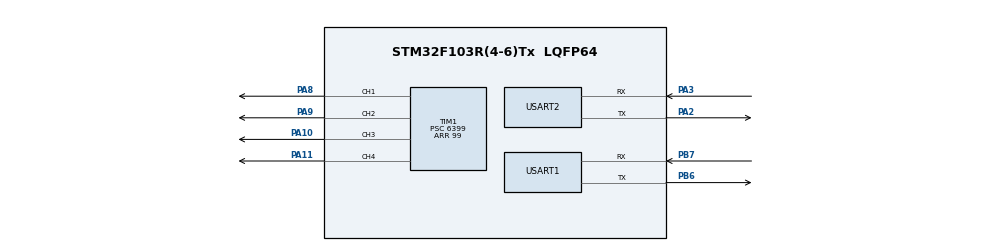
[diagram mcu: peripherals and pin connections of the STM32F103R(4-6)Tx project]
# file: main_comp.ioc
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Dma.Request0=USART1_RX
Dma.Request1=USART1_TX
Dma.USART1_RX.0.Direction=DMA_PERIPH_TO_MEMORY
Dma.USART1_RX.0.Instance=DMA1_Channel5
Dma.USART1_RX.0.MemDataAlignment=DMA_MDATAALIGN_BYTE
Dma.USART1_RX.0.MemInc=DMA_MINC_ENABLE
Dma.USART1_RX.0.Mode=DMA_NORMAL
Dma.USART1_RX.0.PeriphDataAlignment=DMA_PDATAALIGN_BYTE
Dma.USART1_RX.0.PeriphInc=DMA_PINC_DISABLE
Dma.USART1_RX.0.Priority=DMA_PRIORITY_LOW
Dma.USART1_TX.1.Direction=DMA_MEMORY_TO_PERIPH
Dma.USART1_TX.1.Instance=DMA1_Channel4
Dma.USART1_TX.1.MemDataAlignment=DMA_MDATAALIGN_BYTE
Dma.USART1_TX.1.MemInc=DMA_MINC_ENABLE
Dma.USART1_TX.1.Mode=DMA_NORMAL
Dma.USART1_TX.1.PeriphDataAlignment=DMA_PDATAALIGN_BYTE
Dma.USART1_TX.1.PeriphInc=DMA_PINC_DISABLE
Dma.USART1_TX.1.Priority=DMA_PRIORITY_LOW
Mcu.Family=STM32F1
Mcu.Name=STM32F103R(4-6)Tx
Mcu.Package=LQFP64
NVIC.DMA1_Channel4_IRQn=true\:0\:0\:false\:false\:true\:false\:true
NVIC.DMA1_Channel5_IRQn=true\:0\:0\:false\:false\:true\:false\:true
NVIC.PriorityGroup=NVIC_PRIORITYGROUP_4
NVIC.USART2_IRQn=true\:0\:0\:false\:false\:true\:true\:true
PA10.Signal=S_TIM1_CH3
PA11.Signal=S_TIM1_CH4
PA2.Mode=Asynchronous
PA2.Signal=USART2_TX
PA3.Mode=Asynchronous
PA3.Signal=USART2_RX
PA8.Signal=S_TIM1_CH1
PA9.Signal=S_TIM1_CH2
PB6.Mode=Asynchronous
PB6.Signal=USART1_TX
PB7.Mode=Asynchronous
PB7.Signal=USART1_RX
ProjectManager.HeapSize=0x200
ProjectManager.StackSize=0x400
ProjectManager.TargetToolchain=MDK-ARM V5.27
RCC.APB1Freq_Value=8000000
RCC.APB2Freq_Value=8000000
SH.S_TIM1_CH1.0=TIM1_CH1,PWM Generation1 CH1
SH.S_TIM1_CH2.0=TIM1_CH2,PWM Generation2 CH2
SH.S_TIM1_CH3.0=TIM1_CH3,PWM Generation3 CH3
SH.S_TIM1_CH4.0=TIM1_CH4,PWM Generation4 CH4
TIM1.Channel-PWM\ Generation1\ CH1=TIM_CHANNEL_1
TIM1.Channel-PWM\ Generation2\ CH2=TIM_CHANNEL_2
TIM1.Channel-PWM\ Generation3\ CH3=TIM_CHANNEL_3
TIM1.Channel-PWM\ Generation4\ CH4=TIM_CHANNEL_4
TIM1.Period=99
TIM1.Prescaler=6399
USART1.VirtualMode=VM_ASYNC
USART2.VirtualMode=VM_ASYNC
VP_SYS_VS_ND.Mode=No_Debug
board=custom

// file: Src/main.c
/* USER CODE BEGIN Header */
/**
  ******************************************************************************
  * @file           : main.c
  * @brief          : Main program body
  ******************************************************************************
  * @attention
  *
  * <h2><center>&copy; Copyright (c) 2020 STMicroelectronics.
  * All rights reserved.</center></h2>
  *
  * This software component is licensed by ST under BSD 3-Clause license,
  * the "License"; You may not use this file except in compliance with the
  * License. You may obtain a copy of the License at:
  *                        opensource.org/licenses/BSD-3-Clause
  *
  ******************************************************************************
  */
/* USER CODE END Header */

#include "main.h"
#include "stdio.h"
#include "string.h"
#include "stdlib.h"

/* USER CODE BEGIN PM */
void run(uint32_t, uint32_t);
/* USER CODE END PM */

TIM_HandleTypeDef htim1;

UART_HandleTypeDef huart1;
UART_HandleTypeDef huart2;
DMA_HandleTypeDef hdma_usart1_rx;
DMA_HandleTypeDef hdma_usart1_tx;

void SystemClock_Config(void);
static void MX_GPIO_Init(void);
static void MX_DMA_Init(void);
static void MX_TIM1_Init(void);
static void MX_USART1_UART_Init(void);
static void MX_USART2_UART_Init(void);
void run_motor(int, int);

/* USER CODE BEGIN 0 */
char recieved_data[32];
int flag = 0;
/* USER CODE END 0 */

int main(void)
{
  /* USER CODE BEGIN 1 */
	uint16_t val=0;
  /* USER CODE END 1 */

  /* MCU Configuration--------------------------------------------------------*/

  /* Reset of all peripherals, Initializes the Flash interface and the Systick. */
  HAL_Init();

  /* Configure the system clock */
  SystemClock_Config();

  /* Initialize all configured peripherals */
  MX_GPIO_Init();
  MX_DMA_Init();
  MX_TIM1_Init();
  MX_USART1_UART_Init();
  MX_USART2_UART_Init();
  /* USER CODE BEGIN 2 */

	__HAL_UART_ENABLE_IT(&huart2, UART_IT_RXNE);
	HAL_UART_Receive_DMA(&huart2, (uint8_t*)recieved_data, sizeof(recieved_data));

	HAL_TIM_PWM_Start(&htim1, TIM_CHANNEL_1);
	HAL_TIM_PWM_Start(&htim1, TIM_CHANNEL_2);
	HAL_TIM_PWM_Start(&htim1, TIM_CHANNEL_3);
	HAL_TIM_PWM_Start(&htim1, TIM_CHANNEL_4);

  /* USER CODE END 2 */

  /* Infinite loop */
  /* USER CODE BEGIN WHILE */
	int value;
	char speed_str[5];
	char direction_str[5];
	int speed;
	int direction;

  while (1)
  {
		for(int i = 0; i<5; i++){
			speed_str[i] = recieved_data[i];
			direction_str[i] = recieved_data[i+6];
		}

		HAL_UART_Transmit(&huart1, (uint8_t*)speed_str, sizeof(speed_str), HAL_MAX_DELAY);
		HAL_UART_Transmit(&huart1, (uint8_t*)direction_str, sizeof(direction_str), HAL_MAX_DELAY);
		HAL_Delay(1000);
		strcpy(recieved_data, "");

		speed = atoi(speed_str);
		direction = atoi(direction_str);

		run_motor(speed, direction);
  }
  /* USER CODE END 3 */
}

void run_motor(int speed, int direction){
	int pwm_speed = (50*speed - 50000)/1000;
	int pwm_direction = (50*direction - 50000)/1000;

	//Go right
	if(direction > 1000){
		__HAL_TIM_SET_COMPARE(&htim1, TIM_CHANNEL_1, speed);
		__HAL_TIM_SET_COMPARE(&htim1, TIM_CHANNEL_4, speed);

		__HAL_TIM_SET_COMPARE(&htim1, TIM_CHANNEL_2, speed+direction);
		__HAL_TIM_SET_COMPARE(&htim1, TIM_CHANNEL_3, speed+direction);
	}else{
		__HAL_TIM_SET_COMPARE(&htim1, TIM_CHANNEL_1, speed+direction);
		__HAL_TIM_SET_COMPARE(&htim1, TIM_CHANNEL_4, speed+direction);

		__HAL_TIM_SET_COMPARE(&htim1, TIM_CHANNEL_2, speed);
		__HAL_TIM_SET_COMPARE(&htim1, TIM_CHANNEL_3, speed);
	}

}

void HAL_UART_RxCpltCallback(UART_HandleTypeDef *huart){
	__NOP();
}

void SystemClock_Config(void)
{
  RCC_OscInitTypeDef RCC_OscInitStruct = {0};
  RCC_ClkInitTypeDef RCC_ClkInitStruct = {0};

  /** Initializes the CPU, AHB and APB busses clocks
  */
  RCC_OscInitStruct.OscillatorType = RCC_OSCILLATORTYPE_HSI;
  RCC_OscInitStruct.HSIState = RCC_HSI_ON;
  RCC_OscInitStruct.HSICalibrationValue = RCC_HSICALIBRATION_DEFAULT;
  RCC_OscInitStruct.PLL.PLLState = RCC_PLL_NONE;
  if (HAL_RCC_OscConfig(&RCC_OscInitStruct) != HAL_OK)
  {
    Error_Handler();
  }
  /** Initializes the CPU, AHB and APB busses clocks
  */
  RCC_ClkInitStruct.ClockType = RCC_CLOCKTYPE_HCLK|RCC_CLOCKTYPE_SYSCLK
                              |RCC_CLOCKTYPE_PCLK1|RCC_CLOCKTYPE_PCLK2;
  RCC_ClkInitStruct.SYSCLKSource = RCC_SYSCLKSOURCE_HSI;
  RCC_ClkInitStruct.AHBCLKDivider = RCC_SYSCLK_DIV1;
  RCC_ClkInitStruct.APB1CLKDivider = RCC_HCLK_DIV1;
  RCC_ClkInitStruct.APB2CLKDivider = RCC_HCLK_DIV1;

  if (HAL_RCC_ClockConfig(&RCC_ClkInitStruct, FLASH_LATENCY_0) != HAL_OK)
  {
    Error_Handler();
  }
}

static void MX_TIM1_Init(void)
{

  TIM_MasterConfigTypeDef sMasterConfig = {0};
  TIM_OC_InitTypeDef sConfigOC = {0};
  TIM_BreakDeadTimeConfigTypeDef sBreakDeadTimeConfig = {0};

  htim1.Instance = TIM1;
  htim1.Init.Prescaler = 6399;
  htim1.Init.CounterMode = TIM_COUNTERMODE_UP;
  htim1.Init.Period = 99;
  htim1.Init.ClockDivision = TIM_CLOCKDIVISION_DIV1;
  htim1.Init.RepetitionCounter = 0;
  htim1.Init.AutoReloadPreload = TIM_AUTORELOAD_PRELOAD_DISABLE;
  if (HAL_TIM_PWM_Init(&htim1) != HAL_OK)
  {
    Error_Handler();
  }
  sMasterConfig.MasterOutputTrigger = TIM_TRGO_RESET;
  sMasterConfig.MasterSlaveMode = TIM_MASTERSLAVEMODE_DISABLE;
  if (HAL_TIMEx_MasterConfigSynchronization(&htim1, &sMasterConfig) != HAL_OK)
  {
    Error_Handler();
  }
  sConfigOC.OCMode = TIM_OCMODE_PWM1;
  sConfigOC.Pulse = 0;
  sConfigOC.OCPolarity = TIM_OCPOLARITY_HIGH;
  sConfigOC.OCNPolarity = TIM_OCNPOLARITY_HIGH;
  sConfigOC.OCFastMode = TIM_OCFAST_DISABLE;
  sConfigOC.OCIdleState = TIM_OCIDLESTATE_RESET;
  sConfigOC.OCNIdleState = TIM_OCNIDLESTATE_RESET;
  if (HAL_TIM_PWM_ConfigChannel(&htim1, &sConfigOC, TIM_CHANNEL_1) != HAL_OK)
  {
    Error_Handler();
  }
  if (HAL_TIM_PWM_ConfigChannel(&htim1, &sConfigOC, TIM_CHANNEL_2) != HAL_OK)
  {
    Error_Handler();
  }
  if (HAL_TIM_PWM_ConfigChannel(&htim1, &sConfigOC, TIM_CHANNEL_3) != HAL_OK)
  {
    Error_Handler();
  }
  if (HAL_TIM_PWM_ConfigChannel(&htim1, &sConfigOC, TIM_CHANNEL_4) != HAL_OK)
  {
    Error_Handler();
  }
  sBreakDeadTimeConfig.OffStateRunMode = TIM_OSSR_DISABLE;
  sBreakDeadTimeConfig.OffStateIDLEMode = TIM_OSSI_DISABLE;
  sBreakDeadTimeConfig.LockLevel = TIM_LOCKLEVEL_OFF;
  sBreakDeadTimeConfig.DeadTime = 0;
  sBreakDeadTimeConfig.BreakState = TIM_BREAK_DISABLE;
  sBreakDeadTimeConfig.BreakPolarity = TIM_BREAKPOLARITY_HIGH;
  sBreakDeadTimeConfig.AutomaticOutput = TIM_AUTOMATICOUTPUT_DISABLE;
  if (HAL_TIMEx_ConfigBreakDeadTime(&htim1, &sBreakDeadTimeConfig) != HAL_OK)
  {
    Error_Handler();
  }
  HAL_TIM_MspPostInit(&htim1);

}

static void MX_USART1_UART_Init(void)
{

  huart1.Instance = USART1;
  huart1.Init.BaudRate = 115200;
  huart1.Init.WordLength = UART_WORDLENGTH_8B;
  huart1.Init.StopBits = UART_STOPBITS_1;
  huart1.Init.Parity = UART_PARITY_NONE;
  huart1.Init.Mode = UART_MODE_TX_RX;
  huart1.Init.HwFlowCtl = UART_HWCONTROL_NONE;
  huart1.Init.OverSampling = UART_OVERSAMPLING_16;
  if (HAL_UART_Init(&huart1) != HAL_OK)
  {
    Error_Handler();
  }

}

static void MX_USART2_UART_Init(void)
{

  huart2.Instance = USART2;
  huart2.Init.BaudRate = 115200;
  huart2.Init.WordLength = UART_WORDLENGTH_8B;
  huart2.Init.StopBits = UART_STOPBITS_1;
  huart2.Init.Parity = UART_PARITY_NONE;
  huart2.Init.Mode = UART_MODE_TX_RX;
  huart2.Init.HwFlowCtl = UART_HWCONTROL_NONE;
  huart2.Init.OverSampling = UART_OVERSAMPLING_16;
  if (HAL_UART_Init(&huart2) != HAL_OK)
  {
    Error_Handler();
  }

}

static void MX_DMA_Init(void)
{

  /* DMA controller clock enable */
  __HAL_RCC_DMA1_CLK_ENABLE();

  /* DMA interrupt init */
  /* DMA1_Channel4_IRQn interrupt configuration */
  HAL_NVIC_SetPriority(DMA1_Channel4_IRQn, 0, 0);
  HAL_NVIC_EnableIRQ(DMA1_Channel4_IRQn);
  /* DMA1_Channel5_IRQn interrupt configuration */
  HAL_NVIC_SetPriority(DMA1_Channel5_IRQn, 0, 0);
  HAL_NVIC_EnableIRQ(DMA1_Channel5_IRQn);

}

static void MX_GPIO_Init(void)
{

  /* GPIO Ports Clock Enable */
  __HAL_RCC_GPIOA_CLK_ENABLE();
  __HAL_RCC_GPIOB_CLK_ENABLE();

}

void Error_Handler(void)
{
}

/************************ (C) COPYRIGHT STMicroelectronics *****END OF FILE****/
